# R7FA2L1AB register map
Vendor: Renesas Electronics Corporation; Series: RA2L1; File version: 1.20.01
CPU: CM23 r1p0, little endian, MPU, no FPU, VTOR, 2 interrupt priority bits, 32 interrupts
Registers are 8-bit, read-write, reset 0x0 unless marked. A register's access mark holds for its fields unless they carry their own. Offsets are from the block's base; [hi:lo] are bit positions; lines under a group give offsets from that group; {n}, {i} and the like mark numbered series; 'fields as' and 'values as' point back to an identical list.

## RMPU — Renesas Memory Protection Unit
Base 0x40000000
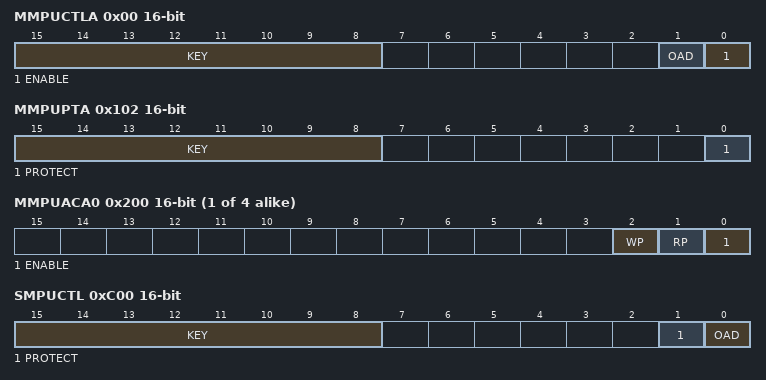
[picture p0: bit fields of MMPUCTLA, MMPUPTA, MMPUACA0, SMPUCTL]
0x00 MMPUCTLA 16-bit — Bus Master MPU Control Register
  [15:8] KEY — Key Code
  [1] OAD — Operation After Detection
    0=Non-maskable interrupt; 1=Reset
  [0] ENABLE — Master Group Enable
    0=Master group A disabled; 1=Master group A enabled
0x102 MMPUPTA 16-bit — Group A Protection of Register
  [15:8] KEY — Key Code
  [0] PROTECT — Protection of Register
    0=All bus master MPU group A register writes are permitted; 1=All bus master MPU group A register writes are protected. Reads are permitted.
{0x200+0x10*i} MMPUACA{i} (i=0..3) 16-bit — Group A Region {i} access control register
  [2] WP — Write Protection
    0=Write permission; 1=Write protection
  [1] RP — Read Protection
    0=Read permission; 1=Read protection
  [0] ENABLE — Region Enable
    0=Group A region n disabled; 1=Group A region n enabled
{0x204+0x10*i} MMPUSA{i} (i=0..3) 32-bit (reset mask 0x3) — Group A Region {i} Start Address Register
  [31:0] MMPUSA — Region Start Address
{0x208+0x10*i} MMPUEA{i} (i=0..3) 32-bit reset 0x3 (reset mask 0x3) — Group A Region {i} End Address Register
  [31:0] MMPUEA — Region End Address
0xC00 SMPUCTL 16-bit — Slave MPU Control Register
  [15:8] KEY — Key Code
  [1] PROTECT — Protection of Register
    0=All bus slave register writes are permitted; 1=All bus slave register writes are protected. Reads are permitted
  [0] OAD — Operation After Detection
    0=Non-maskable interrupt; 1=Reset
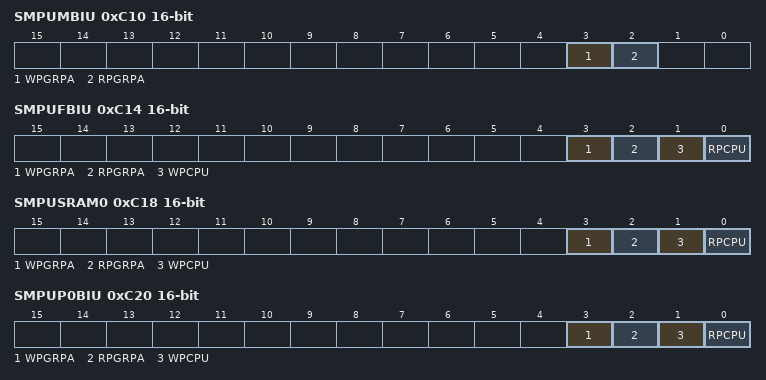
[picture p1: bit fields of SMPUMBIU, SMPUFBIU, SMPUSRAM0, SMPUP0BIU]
0xC10 SMPUMBIU 16-bit — Access Control Register for Memory Bus 1
  [3] WPGRPA — Master MPU Group A Write Protection
    0=Memory protection write for master MPU group A disabled; 1=Memory protection write for master MPU group A enabled
  [2] RPGRPA — Master MPU Group A Read Protection
    0=Memory protection read for master MPU group A disabled; 1=Memory protection read for master MPU group A enabled
0xC14 SMPUFBIU 16-bit — Access Control Register for Internal Peripheral Bus 9
  [3] WPGRPA — Master MPU Group A Write Protection
    0=Memory protection for master MPU group A write disabled; 1=Memory protection for master MPU group A write enabled
  [2] RPGRPA — Master MPU Group A Read Protection
    0=Memory protection for master MPU group A read disabled; 1=Memory protection for master MPU group A read enabled
  [1] WPCPU — CPU Write Protection
    0=Memory protection for CPU write disabled; 1=Memory protection for CPU write enabled
  [0] RPCPU — CPU Read Protection
    0=Memory protection for CPU read disabled; 1=Memory protection for CPU read enabled
0xC18 SMPUSRAM0 16-bit — Access Control Register for Memory Bus 4
  fields as SMPUFBIU
0xC20 SMPUP0BIU 16-bit — Access Control Register for Internal Peripheral Bus 1
  fields as SMPUFBIU
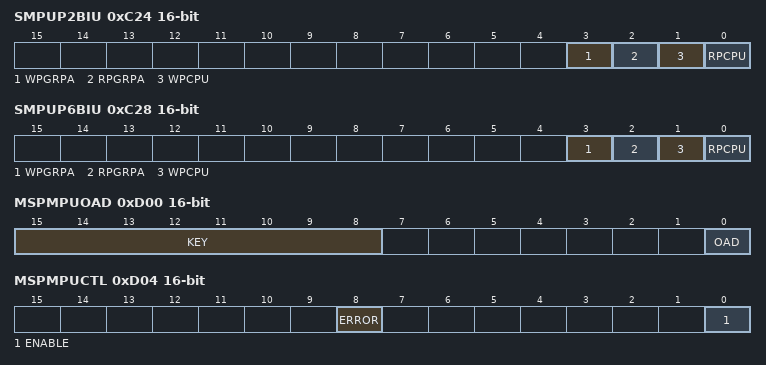
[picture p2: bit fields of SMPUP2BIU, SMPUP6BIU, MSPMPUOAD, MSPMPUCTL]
0xC24 SMPUP2BIU 16-bit — Access Control Register for Internal Peripheral Bus 3
  fields as SMPUFBIU
0xC28 SMPUP6BIU 16-bit — Access Control Register for Internal Peripheral Bus 7
  [3] WPGRPA — Master MPU Group A Write Protection
    0=Master MPU group A write of memory protection disabled; 1=Master MPU group A write of memory protection enabled
  [2] RPGRPA — Master MPU Group A Read Protection
    0=Master MPU group A read of memory protection disabled; 1=Master MPU group A read of memory protection enabled
  [1] WPCPU — CPU Write Protection
    0=CPU write of memory protection disabled; 1=CPU write of memory protection enabled
  [0] RPCPU — CPU Read Protection
    0=CPU read of memory protection disabled; 1=CPU read of memory protection enabled
0xD00 MSPMPUOAD 16-bit — Stack Pointer Monitor Operation After Detection Register
  [15:8] KEY — Key Code
  [0] OAD — Operation after Detection
    0=Non-maskable interrupt; 1=Reset
0xD04 MSPMPUCTL 16-bit (reset mask 0xFEFF) — Stack Pointer Monitor Access Control Register
  [8] ERROR — Stack Pointer Monitor Error Flag
    0=Stack pointer has not overflowed or underflowed; 1=Stack pointer has overflowed or underflowed
  [0] ENABLE — Stack Pointer Monitor Enable
    0=Stack pointer monitor is disabled; 1=Stack pointer monitor is enabled
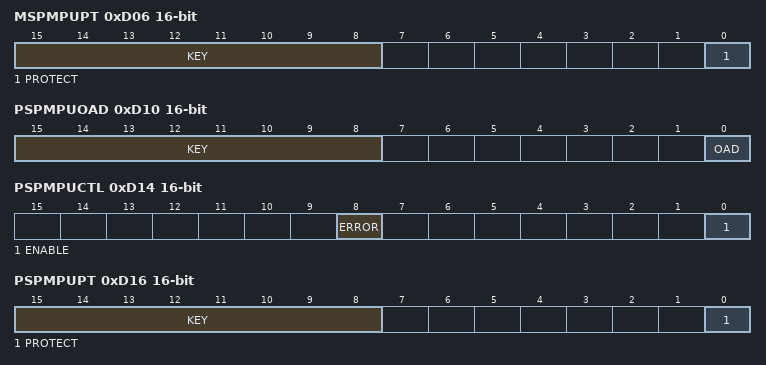
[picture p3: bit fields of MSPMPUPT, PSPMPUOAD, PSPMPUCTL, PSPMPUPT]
0xD06 MSPMPUPT 16-bit — Stack Pointer Monitor Protection Register
  [15:8] KEY — Key Code
  [0] PROTECT — Protection of Register
    0=Stack pointer monitor register writes are permitted; 1=Stack pointer monitor register writes are protected. Reads are permitted
0xD08 MSPMPUSA 32-bit reset not defined — Main Stack Pointer (MSP) Monitor Start Address Register
  [31:0] MSPMPUSA range 0x1FF00000..0x200FFFFC — Region Start Address
0xD0C MSPMPUEA 32-bit reset not defined — Main Stack Pointer (MSP) Monitor End Address Register
  [31:0] MSPMPUEA range 0x1FF00003..0x200FFFFF — Region End Address
0xD10 PSPMPUOAD 16-bit — Stack Pointer Monitor Operation After Detection Register
  fields as MSPMPUOAD
0xD14 PSPMPUCTL 16-bit (reset mask 0xFEFF) — Stack Pointer Monitor Access Control Register
  fields as MSPMPUCTL
0xD16 PSPMPUPT 16-bit — Stack Pointer Monitor Protection Register
  fields as MSPMPUPT
0xD18 PSPMPUSA 32-bit reset not defined — Process Stack Pointer (PSP) Monitor Start Address Register
  [31:0] PSPMPUSA range 0x1FF00000..0x200FFFFC — Region Start Address
0xD1C PSPMPUEA 32-bit reset not defined — Process Stack Pointer (PSP) Monitor End Address Register
  [31:0] PSPMPUEA range 0x1FF00003..0x200FFFFF — Region End Address

## Notices in the file
This software is supplied by Renesas Electronics Corporation and is only intended for
use with Renesas products. No other uses are authorized. This software is owned by
Renesas Electronics Corporation and is protected under all applicable laws, including
copyright laws.
THIS SOFTWARE IS PROVIDED "AS IS" AND RENESAS MAKES NO WARRANTIES REGARDING
THIS SOFTWARE, WHETHER EXPRESS, IMPLIED OR STATUTORY, INCLUDING BUT NOT LIMITED TO
WARRANTIES OF MERCHANTABILITY, FITNESS FOR A PARTICULAR PURPOSE AND NON-INFRINGEMENT.
ALL SUCH WARRANTIES ARE EXPRESSLY DISCLAIMED. TO THE MAXIMUM EXTENT PERMITTED NOT
PROHIBITED BY LAW, NEITHER RENESAS ELECTRONICS CORPORATION NOR ANY OF ITS AFFILIATED
COMPANIES SHALL BE LIABLE FOR ANY DIRECT, INDIRECT, SPECIAL, INCIDENTAL OR CONSEQUENTIAL
DAMAGES FOR ANY REASON RELATED TO THIS SOFTWARE, EVEN IF RENESAS OR ITS AFFILIATES HAVE
BEEN ADVISED OF THE POSSIBILITY OF SUCH DAMAGES.
Renesas reserves the right, without notice, to make changes to this software and to
discontinue the availability of this software. By using this software, you agree to
the additional terms and conditions found by accessing the following link:
http://www.renesas.com/disclaimer
